# IPE3_MMR_ICONT register map
Vendor: Texas Instruments
Peripheral module from a debugger description file (folder DRA74xP_75xP_76xP_77xP).
Registers are 32-bit, read-write, reset 0x0 unless marked. A register's access mark holds for its fields unless they carry their own. Offsets are as the file gives them; lines under a group give offsets from that group; [hi:lo] are bit positions; {n}, {i} and the like mark numbered series; 'fields as' and 'values as' point back to an identical list; <NAME> marks a mode.

## IPE3_MMR_ICONT
0x00 IPE3_PID ro reset not defined — Peripheral ID register
  [31:0] IPE_PID
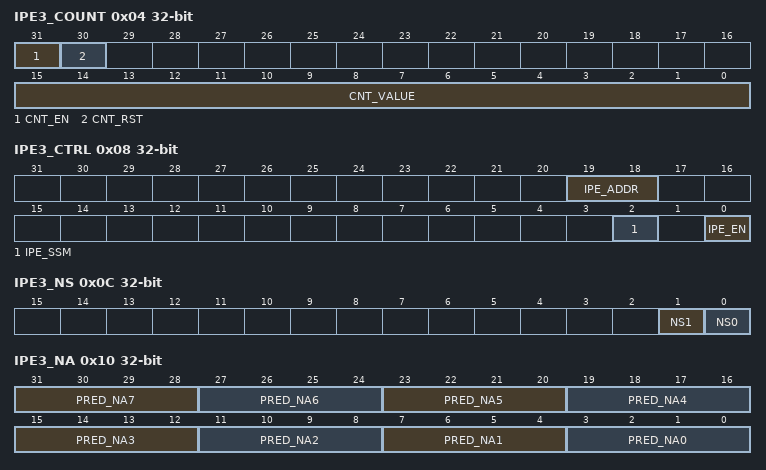
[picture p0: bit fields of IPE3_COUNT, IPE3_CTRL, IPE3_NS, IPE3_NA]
0x04 IPE3_COUNT access per field — IPE3 cycle counter register Determines the cycle number between start of IPE3 core and end (interrupt generation). Can be used for debugging.
  [31] CNT_EN rw — Counter enable 0: Benchmark counter is disabled. 1: Benchmark counter is enabled.
  [30] CNT_RST wo — Counter reset 0: No effect 1: Clear the benchmark counter to 0.
  [15:0] CNT_VALUE ro — Current value of the benchmark counter. When CNT_EN is 1 and IP is busy (IPE3_EN==1), the benchmark counter counts up based on clk. Write access has no effect.
0x08 IPE3_CTRL access not given — IPE3 control register
  [19:18] IPE_ADDR rw — Address of parameter set. Parameter set can have 4 positions in full-view mode and 2 positions for ping-pong view mode. User must set the position to be processed. 0x0: Process first MB. 0x1: Process second MB. 0x2: Process third MB ( full-view mode only). 0x3: Process fourth MB ( full-view mode only). Do not write any value while IPE3 is running (while IPE3_EN is 1).
  [2] IPE_SSM rw — Single-step mode. Stops processing even if continuous mode is set. 0: Normal mode 1: Single-step mode. Do not write any value while IPE3 is running (while IPE3_EN is 1).
  [0] IPE_EN — IPE3 start and status Setting this bit to 1 makes IPE3 start processing. This bit remains 1 while IPE3 is running and is cleared to 0 automatically after processing completes. Writing 0 to this bit has no effect. (access RW RSpecial WSpecial)
0x0C IPE3_NS access per field — Horizontal noise suppression register Do not write any value while IPE3 is running (while IPE3_EN is 1).
  [1] NS1 rw — Bottom block status for horizontal noise suppression 0: Activity is not higher than H_threshold 1: Activity is higher than H_threshold. User can update the value. IPE3 module uses the value to process the next parameter set. No update at noise suppression disable and SACT mode.
  [0] NS0 rw — Top block status for horizontal noise suppression 0: Activity is not higher than H_threshold. 1: Activity is higher than H_threshold. User can update the value. IPE3 module uses the value to process the next parameter set. No update at noise suppression disable and SACT mode.
0x10 IPE3_NA — nA mode register Do not write any value while IPE3 is running (while IPE3_EN is 1).
  [31:28] PRED_NA7 — Intraprediction mode of 4 x 4 block 15 of bottom MB in the previous MB pair. IPE3 does not update in SACT mode.
  [27:24] PRED_NA6 — Intraprediction mode of 4 x 4 block 13 of bottom MB in the previous MB pair. IPE3 does not update in SACT mode.
  [23:20] PRED_NA5 — Intraprediction mode of 4 x 4 block 7 of bottom MB in the previous MB pair. IPE3 does not update in SACT mode.
  [19:16] PRED_NA4 — Intraprediction mode of 4 x 4 block 5 of bottom MB in the previous MB pair. IPE3 does not update in SACT mode.
  [15:12] PRED_NA3 — Intraprediction mode of 4 x 4 block 15 of left MB (or top MB in the previous MB pair in case of MBAFF). IPE3 does not update in SACT mode.
  [11:8] PRED_NA2 — Intraprediction mode of 4 x 4 block 13 of left MB (or top MB in the previous MB pair in case of MBAFF). IPE3 does not update in SACT mode.
  [7:4] PRED_NA1 — Intraprediction mode of 4 x 4 block 7 of left MB (or top MB in the previous MB pair in case of MBAFF). IPE3 does not update in SACT mode.
  [3:0] PRED_NA0 — Intraprediction mode of 4 x 4 block 5 of left MB (or top MB in the previous MB pair in case of MBAFF). IPE3 does not update in SACT mode.
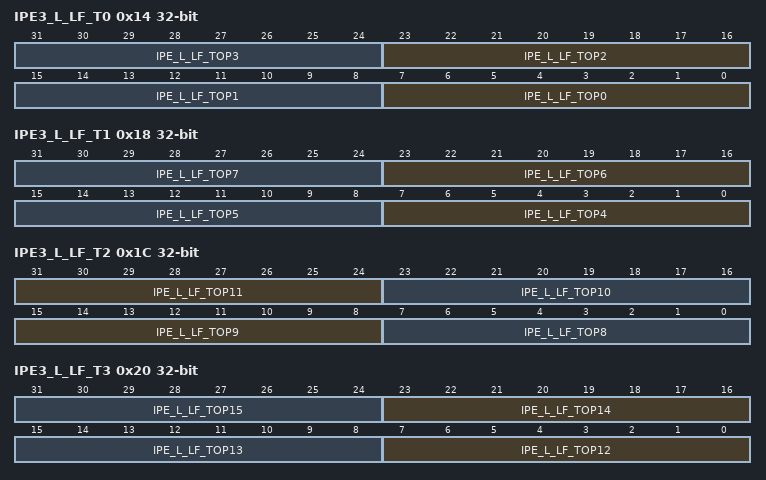
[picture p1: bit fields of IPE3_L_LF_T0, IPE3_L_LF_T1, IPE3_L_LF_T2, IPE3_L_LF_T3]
0x14 IPE3_L_LF_T0 — Luma left neighboring data IPE3 reads this register value as Luma left samples at the beginning of estimation. Right-most current pixels are written at the end of estimation to use data as the left sample of the next MB. Do not write any value while IPE3 is running (while IPE3_EN is 1).
  [8n+7:8n] IPE_L_LF_TOP{n} (n=0..3) — Luma left sample for top MB line {n}. The right-most luminance pixel of top MB line {n} in the left MB. The IPE3 always updates at the end of estimation automatically for the next MB.
0x18 IPE3_L_LF_T1 — Luma left neighboring data IPE3 reads this register value as Luma left samples at the beginning of estimation. Right-most current pixels are written at the end of estimation to use data as the left sample of the next MB. Do not write any value while the IPE3 is running (while IPE3_EN is 1).
  [8n-25:8n-32] IPE_L_LF_TOP{n} (n=4..7) — Luma left sample for top MB line {n}. The right-most luminance pixel of top MB line {n} in the left MB. The IPE3 always updates at the end of estimation automatically for the next MB.
0x1C IPE3_L_LF_T2 — Luma left neighboring data IPE3 reads this register value as Luma left samples at the beginning of estimation. Right-most current pixels are written at the end of estimation to use data as the left sample of the next MB. Do not write any value while the IPE3 is running (while IPE3_EN is 1).
  [31:24] IPE_L_LF_TOP11 — Luma left sample for top MB line 11. The right-most luminance pixel of top MB line 11 in the left MB. The IPE3 always updates at the end of estimation automatically for the next MB.
  [23:16] IPE_L_LF_TOP10 — Luma left sample for top MB line 10. The right-most luminance pixel of top MB line 10 in the left MB. The IPE3 always updates at the end of estimation automatically for the next MB.
  [15:8] IPE_L_LF_TOP9 — Luma left sample for top MB line 9 The right-most luminance pixel of top MB line 9 in the left MB. IPE3 always updates at the end of estimation automatically for the next MB.
  [7:0] IPE_L_LF_TOP8 — Luma left sample for top MB line 8 The right-most luminance pixel of top MB line 8 in the left MB. The IPE3 always updates at the end of estimation automatically for the next MB.
0x20 IPE3_L_LF_T3 — Luma left neighboring data IPE3 reads this register value as Luma left samples at the beginning of estimation. Right-most current pixels are written at the end of estimation to use data as the left sample of the next MB. Do not write any value while the IPE3 is running (while IPE3_EN is 1).
  [8n-89:8n-96] IPE_L_LF_TOP{n} (n=12..15) — Luma left sample for top MB line {n}. The right-most luminance pixel of top MB line {n} in the left MB. The IPE3 always updates at the end of estimation automatically for the next MB.
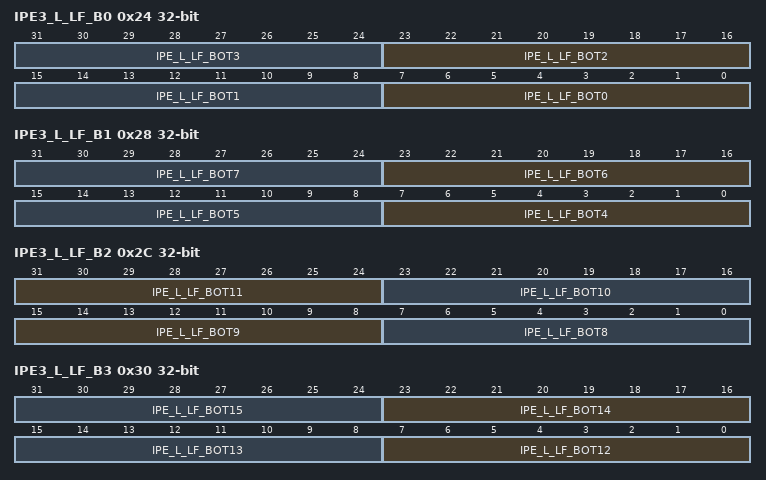
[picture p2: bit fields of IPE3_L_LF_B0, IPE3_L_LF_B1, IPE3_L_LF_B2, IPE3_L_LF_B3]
0x24 IPE3_L_LF_B0 — Luma left neighboring data IPE3 reads this register value as Luma left samples at the beginning of estimation. Right-most current pixels are written at the end of estimation to use data as the left sample of the next MB. Do not write any value while the IPE3 is running (while IPE3_EN is 1).
  [8n+7:8n] IPE_L_LF_BOT{n} (n=0..3) — Luma left sample for bottom MB line {n}. The right-most luminance pixel of bottom MB line {n} in the left MB. The IPE3 always updates at the end of estimation automatically for the next MB.
0x28 IPE3_L_LF_B1 — Luma left neighboring data IPE3 reads this register value as Luma left samples at the beginning of estimation. Right-most current pixels are written at the end of estimation to use data as the left sample of the next MB. Do not write any value while the IPE3 is running (while IPE3_EN is 1).
  [8n-25:8n-32] IPE_L_LF_BOT{n} (n=4..7) — Luma left sample for bottom MB line {n}. The right-most luminance pixel of bottom MB line {n} in the left MB. The IPE3 always updates at the end of estimation automatically for the next MB.
0x2C IPE3_L_LF_B2 — Luma left neighboring data IPE3 reads this register value as Luma left samples at the beginning of estimation. Right-most current pixels are written at the end of estimation to use data as the left sample of the next MB. Do not write any value while the IPE3 is running (while IPE3_EN is 1).
  [31:24] IPE_L_LF_BOT11 — Luma left sample for bottom MB line 11. The right-most luminance pixel of bottom MB line 11 in the left MB. The IPE3 always updates at the end of estimation automatically for the next MB.
  [23:16] IPE_L_LF_BOT10 — Luma left sample for bottom MB line 10. The right-most luminance pixel of bottom MB lin10 in the left MB. The IPE3 always updates at the end of estimation automatically for the next MB.
  [15:8] IPE_L_LF_BOT9 — Luma left sample for bottom MB line 9. The right-most luminance pixel of bottom MB line 9 in the left MB. The IPE3 always updates at the end of estimation automatically for the next MB.
  [7:0] IPE_L_LF_BOT8 — Luma left sample for bottom MB line 8. The right-most luminance pixel of bottom MB line 8 in the left MB. The IPE3 always updates at the end of estimation automatically for the next MB.
0x30 IPE3_L_LF_B3 — Luma left neighboring data IPE3 reads this register value as Luma left samples at the beginning of estimation. Right-most current pixels are written at the end of estimation to use data as the left sample of the next MB. Do not write any value while the IPE3 is running (while IPE3_EN is 1).
  [8n-89:8n-96] IPE_L_LF_BOT{n} (n=12..15) — Luma left sample for bottom MB line {n}. The right-most luminance pixel of bottom MB line {n} in the left MB. The IPE3 always updates at the end of estimation automatically for the next MB.
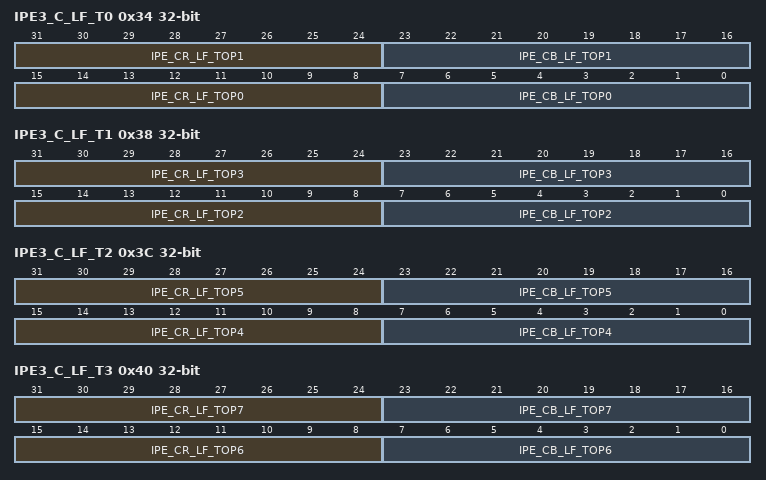
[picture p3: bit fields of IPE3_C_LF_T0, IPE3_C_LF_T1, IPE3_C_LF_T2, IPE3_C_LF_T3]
0x34 IPE3_C_LF_T0 — Chroma left neighboring data IPE3 reads this register value as Chroma left samples at the beginning of estimation. Right-most current pixels are written at the end of estimation to use data as the left sample of the next MB. Do not write any value while the IPE3 is running (while IPE3_EN is 1).
  [31:24] IPE_CR_LF_TOP1 — Left Cr sample of top MB line .1 The right-most Cr pixel of top MB line 1 in the left MB. The IPE3 always updates at the end of estimation automatically for the next MB.
  [23:16] IPE_CB_LF_TOP1 — Left Cb sample of top MB line 1. The right-most Cb pixel of top MB line 1 in the left MB. The IPE3 always updates at the end of estimation automatically for the next MB.
  [15:8] IPE_CR_LF_TOP0 — Left Cr sample of top MB line 0. The right-most Cr pixel of top MB line 0 in the left MB. The IPE3 always updates at the end of estimation automatically for the next MB.
  [7:0] IPE_CB_LF_TOP0 — Left Cb sample of top MB line 0. The right-most Cb pixel of top MB line 0 in the left MB. The IPE3 always updates at the end of estimation automatically for the next MB.
0x38 IPE3_C_LF_T1 — Chroma left neighboring data IPE3 reads this register value as Chroma left samples at the beginning of estimation. Right-most current pixels are written at the end of estimation to use data as the left sample of the next MB. Do not write any value while the IPE3 is running (while IPE3_EN is 1).
  [31:24] IPE_CR_LF_TOP3 — Left Cr sample of top MB line 3. The right-most Cr pixel of top MB line 3 in the left MB. The IPE3 always updates at the end of estimation automatically for the next MB.
  [23:16] IPE_CB_LF_TOP3 — Left Cb sample of top MB line 3. The right-most Cb pixel of top MB line 3 in the left MB. The IPE3 always updates at the end of estimation automatically for the next MB.
  [15:8] IPE_CR_LF_TOP2 — Left Cr sample of top MB line 2. The right-most Cr pixel of top MB line 2 in the left MB. The IPE3 always updates at the end of estimation automatically for the next MB.
  [7:0] IPE_CB_LF_TOP2 — Left Cb sample of top MB line 2. The right-most Cb pixel of top MB line 2 in the left MB. The IPE3 always updates at the end of estimation automatically for the next MB.
0x3C IPE3_C_LF_T2 — Chroma left neighboring data IPE3 reads this register value as chroma left samples at the beginning of estimation. Right-most current pixels are written at the end of estimation to use data as the left sample of the next MB. Do not write any value while the IPE3 is running (while IPE3_EN is 1).
  [31:24] IPE_CR_LF_TOP5 — Left Cr sample of top MB line 5. The right-most Cr pixel of top MB line 5 in the left MB. The IPE3 always updates at the end of estimation automatically for the next MB.
  [23:16] IPE_CB_LF_TOP5 — Left Cb sample of top MB line 5. The right-most Cb pixel of top MB line 5 in the left MB. The IPE3 always updates at the end of estimation automatically for the next MB.
  [15:8] IPE_CR_LF_TOP4 — Left Cr sample of top MB line 4. The right-most Cr pixel of top MB line 4 in the left MB. The IPE3 always updates at the end of estimation automatically for the next MB.
  [7:0] IPE_CB_LF_TOP4 — Left Cb sample of top MB line 4. The right-most Cb pixel of top MB line 4 in the left MB. The IPE3 always updates at the end of estimation automatically for the next MB.
0x40 IPE3_C_LF_T3 — Chroma left neighboring data IPE3 reads this register value as chroma left samples at the beginning of estimation. Right-most current pixels are written at the end of estimation to use data as the left sample of the next MB. Do not write any value while the IPE3 is running (while IPE3_EN is 1).
  [31:24] IPE_CR_LF_TOP7 — Left Cr sample of top MB line 7. The right-most Cr pixel of top MB line 7 in the left MB. The IPE3 always updates at the end of estimation automatically for the next MB.
  [23:16] IPE_CB_LF_TOP7 — Left Cb sample of top MB line 7. The right-most Cb pixel of top MB line 7 in the left MB. The IPE3 always updates at the end of estimation automatically for the next MB.
  [15:8] IPE_CR_LF_TOP6 — Left Cr sample of top MB line 6. The right-most Cr pixel of top line 6 in the left MB. The IPE3 always updates at the end of estimation automatically for the next MB.
  [7:0] IPE_CB_LF_TOP6 — Left Cb sample of top MB line 6. The right-most Cb pixel of top MB line 6 in the left MB. The IPE3 always updates at the end of estimation automatically for the next MB.
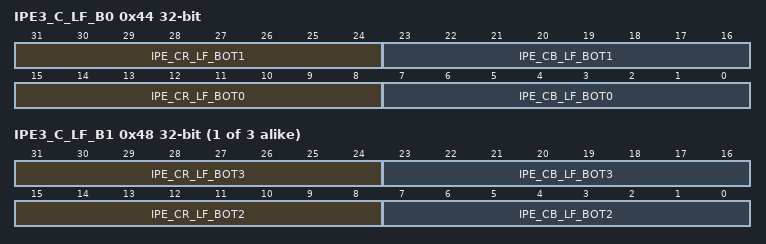
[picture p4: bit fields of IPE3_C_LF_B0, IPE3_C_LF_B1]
0x44 IPE3_C_LF_B0 — Chroma left neighboring data IPE3 reads this register value as chroma left samples at the beginning of estimation. Right-most current pixels are written at the end of estimation to use data as the left sample of the next MB. Do not write any value while the IPE3 is running (while IPE3_EN is 1).
  [31:24] IPE_CR_LF_BOT1 — Left Cr sample of bottom MB line 1. The right-most Cr pixel of bottom MB line 11 in the left MB. The IPE3 always updates at the end of estimation automatically for the next MB.
  [23:16] IPE_CB_LF_BOT1 — Left Cb sample of bottom MB line 1. The right-most Cb pixel of bottom MB line 1 in the left MB. The IPE3 always updates at the end of estimation automatically for the next MB.
  [15:8] IPE_CR_LF_BOT0 — Left Cr sample of bottom MB line 0. The right-most Cr pixel of bottom MB line 0 in the left MB. The IPE3 always updates at the end of estimation automatically for the next MB.
  [7:0] IPE_CB_LF_BOT0 — Left Cb sample of bottom MB line 0. The right-most Cb pixel of bottom MB line 0 in the left MB. The IPE3 always updates at the end of estimation automatically for the next MB.
{0x44+4i} IPE3_C_LF_B{i} (i=1..3) — Chroma left neighboring data IPE3 reads this register value as chroma left samples at the beginning of estimation. Right-most current pixels are written at the end of estimation to use data as the left sample of the next MB. Do not write any value while the IPE3 is running (while IPE3_EN is 1).
  [31:24] IPE_CR_LF_BOT{2i+1} — Left Cr sample of bottom MB line {2i+1}. The right-most Cr pixel of bottom MB line {2i+1} in the left MB. The IPE3 always updates at the end of estimation automatically for the next MB.
  [23:16] IPE_CB_LF_BOT{2i+1} — Left Cb sample of bottom MB line {2i+1}. The right-most Cb pixel of bottom MB line {2i+1} in the left MB. The IPE3 always updates at the end of estimation automatically for the next MB.
  [15:8] IPE_CR_LF_BOT{2i} — Left Cr sample of bottom MB line {2i}. The right-most Cr pixel of bottom MB line {2i} in the left MB. The IPE3 always updates at the end of estimation automatically for the next MB.
  [7:0] IPE_CB_LF_BOT{2i} — Left Cb sample of bottom MB line {2i}. The right-most Cb pixel of bottom MB line {2i} in the left MB. The IPE3 always updates at the end of estimation automatically for the next MB.
